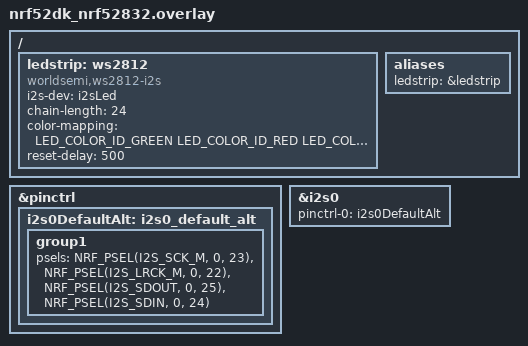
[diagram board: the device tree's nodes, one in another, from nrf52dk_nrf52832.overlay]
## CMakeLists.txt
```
cmake_minimum_required(VERSION 3.20.0)
find_package(Zephyr REQUIRED HINTS $ENV{ZEPHYR_BASE})

project(1.4BreathRingLed)

target_sources(app PRIVATE src/main.c)
```

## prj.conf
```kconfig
CONFIG_SPI=n
CONFIG_LOG=y
CONFIG_SERIAL=y

CONFIG_I2S=y
CONFIG_WS2812_STRIP=y
CONFIG_WS2812_STRIP_I2S=y
CONFIG_LED_STRIP=y
```

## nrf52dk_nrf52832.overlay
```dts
#include <zephyr/dt-bindings/led/led.h>
&pinctrl {
    i2s0DefaultAlt: i2s0_default_alt {  
        group1 {
            /* Default I2S config for the nRF5340, P1.13 is the output */
            psels = <NRF_PSEL(I2S_SCK_M, 0, 23)>,
                    <NRF_PSEL(I2S_LRCK_M, 0, 22)>,
                    <NRF_PSEL(I2S_SDOUT, 0, 25)>,    // Output pin for I2S data
                    <NRF_PSEL(I2S_SDIN, 0, 24)>;     // Input pin for I2S data
        };
    };
};

i2sLed: &i2s0 {  // Renamed to camelCase
    status = "okay";
    pinctrl-0 = <&i2s0DefaultAlt>;  
    pinctrl-names = "default";
};

/{
    ledstrip: ws2812 {  // Renamed to camelCase
        compatible = "worldsemi,ws2812-i2s";

        i2s-dev = <&i2sLed>; 
        chain-length = <24>;  // Number of LEDs in the strip (adjust as needed)
        color-mapping = <LED_COLOR_ID_GREEN
                         LED_COLOR_ID_RED
                         LED_COLOR_ID_BLUE>;
        reset-delay = <500>;
    };

    aliases {
        ledstrip = &ledstrip;  // Updated alias to camelCase
    };
};

/* Enable For Node Configuration Only */
// &pinctrl {
//     uart0Default: uart0_default {  
//         group1 {
//             psels = <NRF_PSEL(UART_TX, 0, 24)>, // TX pin for UART
//                     <NRF_PSEL(UART_RX, 0, 23)>, // RX pin for UART
//                     <NRF_PSEL(UART_RTS, 0, 5)>,  // RTS pin for UART
//                     <NRF_PSEL(UART_CTS, 0, 7)>;  // CTS pin for UART
//         };
//     };

//     uart0Sleep: uart0_sleep {  
//         group1 {
//             psels = <NRF_PSEL(UART_TX, 0, 24)>,    // TX pin for UART
//                     <NRF_PSEL(UART_RX, 0, 23)>,    // RX pin for UART
//                     <NRF_PSEL(UART_RTS, 0, 5)>,    // RTS pin for UART
//                     <NRF_PSEL(UART_CTS, 0, 7)>;    // CTS pin for UART
//             low-power-enable;
//         };
//     };
// };

// &uart0 {
//     status = "okay";
// };
```

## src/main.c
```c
#include <zephyr/logging/log.h>       // Include Zephyr's logging library
#include <zephyr/kernel.h>            // Include Zephyr's kernel library
#include <zephyr/drivers/led_strip.h> // Include the LED strip driver
#include <zephyr/device.h>            // Include Zephyr's device handling library
#include <zephyr/sys/util.h>          // Include Zephyr's utility functions library
#include <zephyr/sys/printk.h>        // Include printk for printing messages

LOG_MODULE_REGISTER(main); // Register the logging module for the main function

#define stripNode DT_ALIAS(ledstrip)                    // Define a symbolic name "stripNode" for the device tree alias "led_strip"
#define stripNumPixels DT_PROP(stripNode, chain_length) // Define a symbolic name "stripNumPixels" for the number of LEDs in the strip

/* Variables that can be changed according to convenience */
#define delayTime 20 // Define a delay time of 20 milliseconds for smooth updates

// Define the structure for RGB colors
struct ledRgb
{
    uint8_t r; // Red component (0-255)
    uint8_t g; // Green component (0-255)
    uint8_t b; // Blue component (0-255)
};

// Macro to define an RGB color
#define RGB(_r, _g, _b) \
    {                   \
        .r = (_r),      \
        .g = (_g),      \
        .b = (_b)}

// Define the color you want to blink (only one color at a time)
static struct ledRgb blinkingColor = RGB(0x00, 0x2f, 0x00); // Green color for blinking effect

// Define an array to hold the color values for each pixel on the strip
struct ledRgb pixels[stripNumPixels];

// Get the LED strip device from the device tree
static const struct device *const strip = DEVICE_DT_GET(stripNode);

// Function to adjust color brightness for breathing effect (blink)
void adjust_brightness(struct ledRgb *color, uint8_t brightness)
{
    color->r = (color->r * brightness) / 255;
    color->g = (color->g * brightness) / 255;
    color->b = (color->b * brightness) / 255;
}

int main(void)
{
    uint8_t brightness = 0; // Variable to control brightness (used for breathing effect)
    int brightnessStep = 5;  // The step for increasing/decreasing brightness

    // Check if the LED strip device is ready
    if (!device_is_ready(strip))
    {
        LOG_ERR("LED strip device not found"); // Log an error if the device is not found
        return -1;                             // Exit the program with an error code
    }

    LOG_INF("Found LED strip device %s", strip->name); // Log the name of the LED strip device

    // Main loop to continuously update the LED strip
    while (1)
    {
        // Clear the pixels array (turn off all LEDs)
        memset(pixels, 0x00, sizeof(pixels));

        // Apply the breathing effect on the color for all LEDs
        for (int ledIdx = 0; ledIdx < stripNumPixels; ledIdx++)
        {
            struct ledRgb currentColor = blinkingColor;
            adjust_brightness(&currentColor, brightness); // Apply brightness adjustment for blinking (breathing effect)
            memcpy(&pixels[ledIdx], &currentColor, sizeof(struct ledRgb));
        }

        // Update the LED strip with the new pixel data
        led_strip_update_rgb(strip, pixels, stripNumPixels);

        // Adjust brightness for blinking (breathing) effect (increase/decrease)
        brightness += brightnessStep;
        if (brightness == 0 || brightness == 255)
        {
            brightnessStep = -brightnessStep; // Reverse the brightness change direction to create blinking
        }

        // Wait for a short period before the next update
        k_msleep(delayTime);
    }

    return 0; // Return 0 indicating the program ended successfully
}
```
